# R7FA0E303 register map
Vendor: Renesas Electronics Corporation; Series: RA0; File version: 1.00.00
CPU: CM23 r1p0, little endian, no MPU, no FPU, VTOR, 2 interrupt priority bits, 64 interrupts
Registers are 16-bit, read-write, reset 0x0 unless marked. A register's access mark holds for its fields unless they carry their own. Offsets are from the block's base; [hi:lo] are bit positions; <NAME> marks a mode.

## IICA — Serial Interface IICA
Base 0x400A3000
0x00 IICA0 8-bit — IICA Shift Register 0
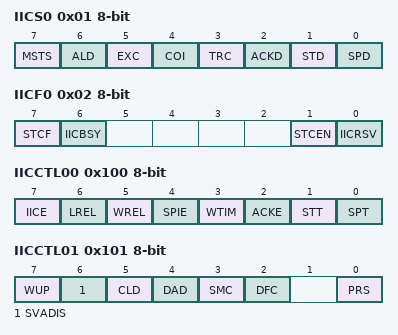
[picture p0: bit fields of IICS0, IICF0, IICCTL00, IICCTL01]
0x01 IICS0 8-bit ro — IICA Status Register 0
  [7] MSTS — Master Status Check Flag
    0=Slave mode status or communication standby status; 1=Master mode communication status
  [6] ALD — Detection of Arbitration Loss
    0=This status means either that there was no arbitration, or that the arbitration result was a win; 1=This status indicates the arbitration result was a loss. The MSTS bit is cleared.
  [5] EXC — Detection of Extension Code Reception
    0=Extension code was not received; 1=Extension code was received. Or, the all address match function is enabled.
  [4] COI — Detection of Matching Addresses
    0=Addresses do not match; 1=Addresses match. Or, the all address match function is enabled.
  [3] TRC — Detection of Transmit and Receive Status
    0=Receive status (other than transmit status). The SDAA0 line is set for high impedance.; 1=Transmit status. The value in the SOn latch is enabled for output to the SDAA0 line (valid starting at the falling edge of the first byte's ninth clock).
  [2] ACKD — Detection of Acknowledge (ACK)
    0=Acknowledge was not detected; 1=Acknowledge was detected
  [1] STD — Detection of Start Condition
    0=Start condition was not detected; 1=Start condition was detected. This indicates that the address transfer period is in effect.
  [0] SPD — Detection of Stop Condition
    0=Stop condition was not detected; 1=Stop condition was detected. Communication of the master device is terminated and the bus is released.
0x02 IICF0 8-bit — IICA Flag Register 0
  [7] STCF ro — IICCTL00.STT Clear Flag
    0=Generate start condition; 1=Start condition generation unsuccessful: clear the IICCTL00.STT flag
  [6] IICBSY ro — I2C Bus Status Flag
    0=Bus release status (communication initial status when STCEN = 1); 1=Bus communication status (communication initial status when STCEN = 0)
  [1] STCEN — Initial Start Enable Trigger
    0=After operation is enabled (IICCTL00.IICE = 1), enable generation of a start condition upon detection of a stop condition; 1=After operation is enabled (IICCTL00.IICE = 1), enable generation of a start condition without detecting a stop condition
  [0] IICRSV — Communication Reservation Function Disable Bit
    0=Enable communication reservation; 1=Disable communication reservation
0x100 IICCTL00 8-bit — IICA Control Register 00
  [7] IICE — I2C Operation Enable
    0=Stop operation. Reset the IICA status register 0 (IICS0). Stop internal operation.; 1=Enable operation
  [6] LREL — Exit from Communications
    0=Normal operation; 1=IICA exits from the current communications and sets communication standby status. This setting is automatically cleared to 0 after being executed. Its uses include cases in which a locally irrelevant extension code has been received. The SCLA0 and SDAA0 lines are set to high impedance. The following flags of IICA control register 00 (IICCTL00) and the IICA status register 0 (IICS0) are cleared to 0. IICCTL00.STT IICCTL00.SPT IICS0.MSTS IICS0.EXC IICS0.COI IICS0.TRC IICS0.ACKD IICS0.STD
  [5] WREL — Release from the Clock Stretch State
    0=The interface is not released from the clock stretch state; 1=The interface is released from the clock stretch state. After release from the clock stretch state, this bit is automatically cleared to 0.
  [4] SPIE — Enable and Disable Generation of Interrupt Request when Stop Condition is Detected
    0=Disable; 1=Enable
  [3] WTIM — Control of Clock Stretching and Interrupt Request Generation
    0=An interrupt request is generated on the falling edge of the 8th clock cycle. Master mode: After the output of eight clock pulses, the clock output is set to the low level and clock stretching is set. Slave mode: After the input of eight clock pulses, the clock is set to the low level and clock stretching is set for the master device.; 1=An interrupt request is generated on the falling edge of the 9th clock cycle. Master mode: After the output of nine clock pulses, the clock output is set to the low level and clock stretching is set. Slave mode: After the input of 9 clock pulses, the clock is set to the low level and clock stretching is set for the master device.
  [2] ACKE — Acknowledgment Control
    0=Disable acknowledgment; 1=Enable acknowledgment. During the 9th clock period, the SDAA0 line is set to low level.
  [1] STT — Start Condition Trigger
    0=Do not generate a start condition; 1=When bus is released (in communication standby status, when IICF0.IICBSY = 0): If this bit is set to 1, a start condition is generated (startup as the master mode). When a third party is communicating: When communication reservation function is enabled (IICF0.IICRSV = 0) Functions as the start condition reservation flag. When set to 1, automatically generates a start condition after the bus is released. When communication reservation function is disabled (IICF0.IICRSV = 1) Even if this bit is set to 1, the STT bit is cleared and the STT clear flag (IICF0.STCF) is set to 1. No start condition is generated. In the clock stretch state (for a master device): Generates a restart condition after release from the clock stretch state.
  [0] SPT — Stop Condition Trigger
    0=Stop condition is not generated; 1=Stop condition is generated (End of transfer as master device)
0x101 IICCTL01 8-bit — IICA Control Register 01
  [7] WUP — Control of Address Match Wakeup
    0=Stops operation of address match wakeup function in Software Standby mode; 1=Enables operation of address match wakeup function in Software Standby mode
  [6] SVADIS — Address Match Disabling Flag
    0=Disables the all address match function; 1=Enables the all address match function
  [5] CLD ro — Detection of SCLA0 Pin Level (Valid Only when IICCTL00.IICE = 1)
    0=The SCLA0 pin was detected at low level; 1=The SCLA0 pin was detected at high level
  [4] DAD ro — Detection of SDAA0 Pin Level (Valid Only when IICCTL00.IICE = 1)
    0=The SDAA0 pin was detected at low level; 1=The SDAA0 pin was detected at high level
  [3] SMC — Operation Mode Switching
    0=Operates in standard mode (fastest transfer rate: 100 kbps); 1=Operates in fast mode (fastest transfer rate: 400 kbps) or fast mode plus (fastest transfer rate: 1 Mbps)
  [2] DFC — Digital Filter Operation Control
    0=Digital filter off; 1=Digital filter on
  [0] PRS — IICA Operation Clock (fMCK)
    0=Selects PCLKB (1 MHz ≤ PCLKB ≤ 20 MHz); 1=Selects PCLKB/2 (20 MHz < PCLKB)
0x102 IICWL0 8-bit reset 0xFF — IICA Low-level Width Setting Register 0
0x103 IICWH0 8-bit reset 0xFF — IICA High-level Width Setting Register 0
0x104 SVA0 8-bit — Slave Address Register 0
  [7:1] A — 7-bit Local Address when in Slave Mode of Unit 0
